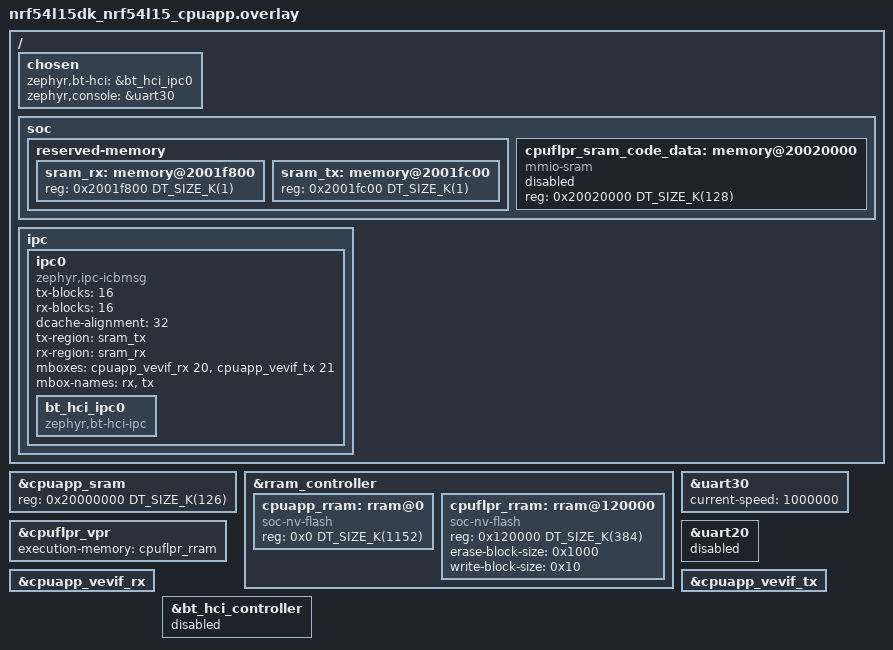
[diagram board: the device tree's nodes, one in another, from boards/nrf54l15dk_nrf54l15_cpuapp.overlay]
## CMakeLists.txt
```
# SPDX-License-Identifier: Apache-2.0

cmake_minimum_required(VERSION 3.28.0)

find_package(Zephyr REQUIRED HINTS $ENV{ZEPHYR_BASE})
project(peripheral_hr)

FILE(GLOB app_sources src/*.c)
target_sources(app PRIVATE
  ${app_sources}
  )

zephyr_library_include_directories(${ZEPHYR_BASE}/samples/bluetooth)
```

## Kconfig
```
# Copyright 2024 Nordic Semiconductor ASA
# SPDX-License-Identifier: Apache-2.0

if "$(FILE_SUFFIX)" = "extended"

# Increase Advertising Data Length, as Complete Local Name too needs to be
# placed in the AUX_ADV_IND PDU compared to when it is placed in ADV_SCAN_IND
# PDU in the case of legacy advertising.
configdefault BT_CTLR_ADV_DATA_LEN_MAX
	default 36

endif


if "$(FILE_SUFFIX)" = "phy_coded"

# Increase Advertising Data Length, as Complete Local Name too needs to be
# placed in the AUX_ADV_IND PDU compared to when it is placed in ADV_SCAN_IND
# PDU in the case of legacy advertising.
configdefault BT_CTLR_ADV_DATA_LEN_MAX
	default 36

configdefault BT_CTLR_PHY_CODED
	default y

endif


source "Kconfig"
```

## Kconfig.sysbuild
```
# Copyright 2023-2024 Nordic Semiconductor ASA
# SPDX-License-Identifier: Apache-2.0

source "share/sysbuild/Kconfig"

config NET_CORE_BOARD
	string
	default "nrf54l15dk/nrf54l15/cpuflpr" if $(BOARD) = "nrf54l15dk"
	default "nrf5340dk/nrf5340/cpunet" if $(BOARD) = "nrf5340dk"
	default "nrf5340_audio_dk/nrf5340/cpunet" if $(BOARD) = "nrf5340_audio_dk"
	default "nrf5340bsim/nrf5340/cpunet" if $(BOARD_TARGET_STRING) = "NRF5340BSIM_NRF5340_CPUAPP"

config NET_CORE_IMAGE_HCI_IPC
	bool "HCI IPC image on network core"
	default y
	depends on NET_CORE_BOARD != ""
```

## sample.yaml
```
sample:
  name: Bluetooth Peripheral HR
  description: Demonstrates the HR (Heart Rate) GATT Service
tests:
  sample.bluetooth.peripheral_hr:
    harness: bluetooth
    platform_allow:
      - qemu_cortex_m3
      - qemu_x86
      - nrf51dk/nrf51822
      - nrf52_bsim
      - nrf52dk/nrf52832
      - nrf52840dk/nrf52840
      - nrf5340bsim/nrf5340/cpuapp
      - nrf5340dk/nrf5340/cpuapp
      - nrf54l15bsim/nrf54l15/cpuapp
      - nrf54l15dk/nrf54l15/cpuapp
      - ophelia4ev/nrf54l15/cpuapp
      - nrf54lm20dk/nrf54lm20a/cpuapp
    integration_platforms:
      - qemu_cortex_m3
      - nrf51dk/nrf51822
      - nrf52_bsim
      - nrf52dk/nrf52832
      - nrf52840dk/nrf52840
      - nrf5340bsim/nrf5340/cpuapp
      - nrf5340dk/nrf5340/cpuapp
      - nrf54l15bsim/nrf54l15/cpuapp
      - nrf54l15dk/nrf54l15/cpuapp
      - ophelia4ev/nrf54l15/cpuapp
      - nrf54lm20dk/nrf54lm20a/cpuapp
    tags: bluetooth
    sysbuild: true
  sample.bluetooth.peripheral_hr.minimal:
    harness: bluetooth
    platform_allow:
      - qemu_cortex_m3
    integration_platforms:
      - qemu_cortex_m3
    extra_args:
      - CONF_FILE=prj_minimal.conf
    tags: bluetooth
  sample.bluetooth.peripheral_hr.bt_ll_sw_split.minimal:
    harness: bluetooth
    platform_allow:
      - bbc_microbit
      - nrf52dk/nrf52832
      - nrf54l15dk/nrf54l15/cpuapp
    integration_platforms:
      - bbc_microbit
      - nrf52dk/nrf52832
      - nrf54l15dk/nrf54l15/cpuapp
    extra_args:
      - CONF_FILE=prj_minimal.conf
      - EXTRA_CONF_FILE=overlay-bt_ll_sw_split-minimal.conf
    tags: bluetooth
  sample.bluetooth.peripheral_hr.bt_ll_sw_split.extended:
    harness: bluetooth
    platform_allow:
      - nrf52_bsim
      - nrf52dk/nrf52832
      - nrf52840dk/nrf52840
    integration_platforms:
      - nrf52_bsim
      - nrf52dk/nrf52832
      - nrf52840dk/nrf52840
    extra_args:
      - EXTRA_CONF_FILE=overlay-extended.conf
    tags: bluetooth
  sample.bluetooth.peripheral_hr.multicore.bt_ll_sw_split.extended:
    harness: bluetooth
    platform_allow:
      - nrf5340bsim/nrf5340/cpuapp
      - nrf5340dk/nrf5340/cpuapp
    integration_platforms:
      - nrf5340bsim/nrf5340/cpuapp
      - nrf5340dk/nrf5340/cpuapp
    extra_args:
      - CONFIG_BT_EXT_ADV=y
    tags: bluetooth
    sysbuild: true
  sample.bluetooth.peripheral_hr.bt_ll_sw_split.phy_coded:
    harness: bluetooth
    platform_allow:
      - nrf52_bsim
      - nrf52dk/nrf52832
      - nrf52840dk/nrf52840
    integration_platforms:
      - nrf52_bsim
      - nrf52dk/nrf52832
      - nrf52840dk/nrf52840
    extra_args:
      - EXTRA_CONF_FILE=overlay-phy_coded.conf
    tags: bluetooth
    sysbuild: true
  sample.bluetooth.peripheral_hr.multicore.bt_ll_sw_split.phy_coded:
    harness: bluetooth
    platform_allow:
      - nrf5340bsim/nrf5340/cpuapp
      - nrf5340dk/nrf5340/cpuapp
    integration_platforms:
      - nrf5340bsim/nrf5340/cpuapp
      - nrf5340dk/nrf5340/cpuapp
    extra_args:
      - CONFIG_BT_EXT_ADV=y
    tags: bluetooth
    sysbuild: true
  sample.bluetooth.peripheral_hr.bt_ll_sw_split.dual_timer:
    harness: bluetooth
    platform_allow:
      - nrf52_bsim
      - nrf52dk/nrf52832
      - nrf54l15bsim/nrf54l15/cpuapp
      - nrf54l15dk/nrf54l15/cpuapp
    integration_platforms:
      - nrf52_bsim
      - nrf52dk/nrf52832
      - nrf54l15bsim/nrf54l15/cpuapp
      - nrf54l15dk/nrf54l15/cpuapp
    extra_args:
      - CONFIG_BT_CTLR_ADVANCED_FEATURES=y
      - CONFIG_BT_CTLR_SW_SWITCH_SINGLE_TIMER=n
    tags: bluetooth
  sample.bluetooth.peripheral_hr.bt_ll_sw_split.single_timer:
    harness: bluetooth
    platform_allow:
      - nrf52_bsim
      - nrf52dk/nrf52832
      - nrf54l15bsim/nrf54l15/cpuapp
      - nrf54l15dk/nrf54l15/cpuapp
    integration_platforms:
      - nrf52_bsim
      - nrf52dk/nrf52832
      - nrf54l15bsim/nrf54l15/cpuapp
      - nrf54l15dk/nrf54l15/cpuapp
    extra_args:
      - CONFIG_BT_CTLR_ADVANCED_FEATURES=y
      - CONFIG_BT_CTLR_SW_SWITCH_SINGLE_TIMER=y
    tags: bluetooth
  sample.bluetooth.peripheral_hr_rv32m1_vega_openisa_rv32m1_ri5cy:
    platform_allow: rv32m1_vega/openisa_rv32m1/ri5cy
    tags: bluetooth
    build_only: true
  sample.bluetooth.peripheral_hr.frdm_kw41z_shield:
    harness: bluetooth
    depends_on: arduino_serial
    tags: bluetooth
    extra_args: SHIELD=frdm_kw41z
```

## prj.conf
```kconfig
CONFIG_BT=y
CONFIG_LOG=y
CONFIG_BT_SMP=y
CONFIG_BT_PERIPHERAL=y
CONFIG_BT_DIS=y
CONFIG_BT_DIS_PNP=n
CONFIG_BT_BAS=y
CONFIG_BT_HRS=y
CONFIG_BT_DEVICE_NAME="Zephyr Heartrate Sensor"
CONFIG_BT_DEVICE_APPEARANCE=833

CONFIG_SYSTEM_WORKQUEUE_STACK_MIN_SIZE_APP=1100
```

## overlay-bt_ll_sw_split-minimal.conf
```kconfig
# Zephyr open source Bluetooth Low Energy Controller
CONFIG_BT_LL_SW_SPLIT=y

# Disable Bluetooth controller features not needed
CONFIG_BT_CTLR_CONN_PARAM_REQ=n
CONFIG_BT_CTLR_EXT_REJ_IND=n
CONFIG_BT_CTLR_PER_INIT_FEAT_XCHG=n
CONFIG_BT_CTLR_MIN_USED_CHAN=n

# Buffer sizes
CONFIG_BT_CTLR_RX_BUFFERS=1

# Use link time optimization for code size reduction
CONFIG_ISR_TABLES_LOCAL_DECLARATION=y
CONFIG_LTO=y

# Generate .lst file, to find HCI h/w error event given PC
CONFIG_OUTPUT_DISASSEMBLY=y
CONFIG_OUTPUT_DISASSEMBLY_WITH_SOURCE=y
```

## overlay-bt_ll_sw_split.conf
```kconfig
# Configuration file to be used as an overlay to the hci_ipc sample for multi-core boards

CONFIG_BT_EXT_ADV=y

# Enable Coded PHY support
CONFIG_BT_CTLR_PHY_CODED=y

# Increase Advertising Data Length, as Complete Local Name too needs to be
# placed in the AUX_ADV_IND PDU compared to when it is placed in ADV_SCAN_IND
# PDU in the case of legacy advertising.
CONFIG_BT_CTLR_ADV_DATA_LEN_MAX=36
```

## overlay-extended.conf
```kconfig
CONFIG_BT_EXT_ADV=y

# Increase Advertising Data Length, as Complete Local Name too needs to be
# placed in the AUX_ADV_IND PDU compared to when it is placed in ADV_SCAN_IND
# PDU in the case of legacy advertising.
CONFIG_BT_CTLR_ADV_DATA_LEN_MAX=36
```

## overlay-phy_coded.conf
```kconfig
CONFIG_BT_EXT_ADV=y

# Enable Coded PHY support
CONFIG_BT_CTLR_PHY_CODED=y

# Increase Advertising Data Length, as Complete Local Name too needs to be
# placed in the AUX_ADV_IND PDU compared to when it is placed in ADV_SCAN_IND
# PDU in the case of legacy advertising.
CONFIG_BT_CTLR_ADV_DATA_LEN_MAX=36
```

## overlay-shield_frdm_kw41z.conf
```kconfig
#
# Copyright (c) 2018, NXP
#
# SPDX-License-Identifier: Apache-2.0
#

CONFIG_SHIELD_FRDM_KW41Z=y
```

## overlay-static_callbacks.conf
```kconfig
# Disable connection dynamic callbacks
CONFIG_BT_CONN_DYNAMIC_CALLBACKS=n
```

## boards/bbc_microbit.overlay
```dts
/*
 * SPDX-FileCopyrightText: Copyright The Zephyr Project Contributors
 * SPDX-License-Identifier: Apache-2.0
 */

/* The sample does not use the accelerometer. With its node enabled the driver
 * is built in as soon as the sensor subsystem is on, which the clock
 * calibration turns on, and brings the I2C driver with it.
 */
&mma8653fc {
	status = "disabled";
};
```

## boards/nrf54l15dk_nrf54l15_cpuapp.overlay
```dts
/*
 * Copyright (c) 2026 Nordic Semiconductor ASA
 *
 * SPDX-License-Identifier: Apache-2.0
 */

/ {
	chosen {
		zephyr,bt-hci = &bt_hci_ipc0;
		zephyr,console = &uart30;
	};

	soc {
		reserved-memory {
			#address-cells = <1>;
			#size-cells = <1>;

			sram_rx: memory@2001f800 {
				reg = <0x2001f800 DT_SIZE_K(1)>;
			};

			sram_tx: memory@2001fc00 {
				reg = <0x2001fc00 DT_SIZE_K(1)>;
			};
		};

		cpuflpr_sram_code_data: memory@20020000 {
			compatible = "mmio-sram";
			reg = <0x20020000 DT_SIZE_K(128)>;
			ranges = <0x0 0x20020000 DT_SIZE_K(128)>;
			status = "reserved";
			#address-cells = <1>;
			#size-cells = <1>;
		};
	};

	ipc {
		ipc0: ipc0 {
			compatible = "zephyr,ipc-icbmsg";
			tx-blocks = <16>;
			rx-blocks = <16>;
			dcache-alignment = <32>;
			tx-region = <&sram_tx>;
			rx-region = <&sram_rx>;
			mboxes = <&cpuapp_vevif_rx 20>, <&cpuapp_vevif_tx 21>;
			mbox-names = "rx", "tx";
			status = "okay";

			bt_hci_ipc0: bt_hci_ipc0 {
				compatible = "zephyr,bt-hci-ipc";
				status = "okay";
			};
		};
	};
};

&cpuapp_sram {
	reg = <0x20000000 DT_SIZE_K(126)>;
	ranges = <0x0 0x20000000 DT_SIZE_K(126)>;
};

&rram_controller {
	cpuapp_rram: rram@0 {
		compatible = "soc-nv-flash";
		reg = <0x0 DT_SIZE_K(1152)>;
		ranges = <0x0 0 DT_SIZE_K(1152)>;
	};

	cpuflpr_rram: rram@120000 {
		compatible = "soc-nv-flash";
		reg = <0x120000 DT_SIZE_K(384)>;
		ranges = <0x0 0x120000 DT_SIZE_K(384)>;
		erase-block-size = <0x1000>;
		write-block-size = <0x10>;
		#address-cells = <1>;
		#size-cells = <1>;
	};
};

&cpuflpr_vpr {
	status = "okay";
	execution-memory = <&cpuflpr_rram>;
	/*
	 * execution-memory = <&cpuflpr_sram_code_data>;
	 * source-memory = <&cpuflpr_rram>;
	 */
};

&uart30 {
	current-speed = <1000000>;
	status = "okay";
};

&uart20 {
	status = "disabled";
};

&cpuapp_vevif_rx {
	status = "okay";
};

&cpuapp_vevif_tx {
	status = "okay";
};

&bt_hci_controller {
	status = "disabled";
};
```

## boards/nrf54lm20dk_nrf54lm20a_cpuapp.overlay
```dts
/*
 * Copyright (c) 2026 Nordic Semiconductor ASA
 *
 * SPDX-License-Identifier: Apache-2.0
 */

/ {
	chosen {
		zephyr,bt-hci = &bt_hci_ipc0;
		zephyr,console = &uart30;
	};

	soc {
		reserved-memory {
			#address-cells = <1>;
			#size-cells = <1>;

			sram_rx: memory@2001F800 {
				reg = <0x2001F800 DT_SIZE_K(1)>;
			};

			sram_tx: memory@2001FC00 {
				reg = <0x2001FC00 DT_SIZE_K(1)>;
			};
		};

		cpuflpr_sram_code_data: memory@20020000 {
			compatible = "mmio-sram";
			reg = <0x20020000 DT_SIZE_K(128)>;
			ranges = <0x0 0x20020000 DT_SIZE_K(128)>;
			status = "reserved";
			#address-cells = <1>;
			#size-cells = <1>;
		};
	};

	ipc {
		ipc0: ipc0 {
			compatible = "zephyr,ipc-icbmsg";
			tx-blocks = <32>;
			rx-blocks = <32>;
			dcache-alignment = <32>;
			tx-region = <&sram_tx>;
			rx-region = <&sram_rx>;
			mboxes = <&cpuapp_vevif_rx 20>, <&cpuapp_vevif_tx 21>;
			mbox-names = "rx", "tx";
			status = "okay";

			bt_hci_ipc0: bt_hci_ipc0 {
				compatible = "zephyr,bt-hci-ipc";
				status = "okay";
			};
		};
	};
};

&cpuapp_sram {
	reg = <0x20000000 DT_SIZE_K(126)>;
	ranges = <0x0 0x20000000 DT_SIZE_K(126)>;
};

&rram_controller {
	cpuapp_rram: rram@0 {
		compatible = "soc-nv-flash";
		reg = <0x0 DT_SIZE_K(1280)>;
		ranges = <0x0 0 DT_SIZE_K(1280)>;
	};

	cpuflpr_rram: rram@140000 {
		compatible = "soc-nv-flash";
		reg = <0x140000 DT_SIZE_K(256)>;
		ranges = <0x0 0x140000 DT_SIZE_K(256)>;
		erase-block-size = <0x1000>;
		write-block-size = <0x10>;
		#address-cells = <1>;
		#size-cells = <1>;
	};
};

&cpuflpr_vpr {
	status = "okay";
	execution-memory = <&cpuflpr_rram>;
	/*
	 * execution-memory = <&cpuflpr_sram_code_data>;
	 * source-memory = <&cpuflpr_rram>;
	 */
};

&uart30 {
	current-speed = <1000000>;
	status = "okay";
};

&uart20 {
	status = "disabled";
};

&cpuapp_vevif_rx {
	status = "okay";
};

&cpuapp_vevif_tx {
	status = "okay";
};

&bt_hci_controller {
	status = "disabled";
};
```

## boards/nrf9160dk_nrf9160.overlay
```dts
/ {
	chosen {
		zephyr,bt-uart=&uart2;
	};
};

&uart2 {
	compatible = "nordic,nrf-uarte";
	current-speed = <1000000>;
	status = "okay";
	tx-pin = <18>;
	rx-pin = <17>;
	rts-pin = <21>;
	cts-pin = <19>;
	hw-flow-control;
};
```

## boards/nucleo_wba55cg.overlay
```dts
/*
 * SPDX-License-Identifier: Apache-2.0
 *
 * Copyright (c) 2023 STMicroelectronics
 */

/ {
	/* Change min residency time to ease power consumption measurement */
	cpus {
		cpu0: cpu@0 {
			cpu-power-states = <&stop0 &stop1 &standby>;
		};

		power-states {
			standby: state2 {
				compatible = "zephyr,power-state";
				power-state-name = "suspend-to-ram";
				substate-id = <1>;
				min-residency-us = <10000>;
				exit-latency-us = <1000>;
			};
		};
	};

};

&lptim1 {
	status = "okay";
};
```

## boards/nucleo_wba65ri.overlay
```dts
/*
 * SPDX-License-Identifier: Apache-2.0
 *
 * Copyright (c) 2023 STMicroelectronics
 */

/ {
	/* Change min residency time to ease power consumption measurement */
	cpus {
		cpu0: cpu@0 {
			cpu-power-states = <&stop0 &stop1 &standby>;
		};

		power-states {
			standby: state2 {
				compatible = "zephyr,power-state";
				power-state-name = "suspend-to-ram";
				substate-id = <1>;
				min-residency-us = <10000>;
				exit-latency-us = <1000>;
			};
		};
	};
};

&lptim1 {
	status = "okay";
};
```

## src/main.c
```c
/* main.c - Application main entry point */

/*
 * Copyright (c) 2024 Nordic Semiconductor ASA
 * Copyright (c) 2015-2016 Intel Corporation
 *
 * SPDX-License-Identifier: Apache-2.0
 */

#include <zephyr/device.h>
#include <zephyr/devicetree.h>

#include <zephyr/bluetooth/bluetooth.h>
#include <zephyr/bluetooth/hci.h>
#include <zephyr/bluetooth/conn.h>
#include <zephyr/bluetooth/uuid.h>
#include <zephyr/bluetooth/gatt.h>
#include <zephyr/bluetooth/services/bas.h>
#include <zephyr/bluetooth/services/hrs.h>

static bool hrf_ntf_enabled;

static const struct bt_data ad[] = {
	BT_DATA_BYTES(BT_DATA_FLAGS, (BT_LE_AD_GENERAL | BT_LE_AD_NO_BREDR)),
	BT_DATA_BYTES(BT_DATA_UUID16_ALL,
		      BT_UUID_16_ENCODE(BT_UUID_HRS_VAL),
		      BT_UUID_16_ENCODE(BT_UUID_BAS_VAL),
		      BT_UUID_16_ENCODE(BT_UUID_DIS_VAL)),
#if defined(CONFIG_BT_EXT_ADV)
	BT_DATA(BT_DATA_NAME_COMPLETE, CONFIG_BT_DEVICE_NAME, sizeof(CONFIG_BT_DEVICE_NAME) - 1),
#endif /* CONFIG_BT_EXT_ADV */
};

#if !defined(CONFIG_BT_EXT_ADV)
static const struct bt_data sd[] = {
	BT_DATA(BT_DATA_NAME_COMPLETE, CONFIG_BT_DEVICE_NAME, sizeof(CONFIG_BT_DEVICE_NAME) - 1),
};
#endif /* !CONFIG_BT_EXT_ADV */

enum {
	STATE_CONNECTED,
	STATE_DISCONNECTED,

	STATE_BITS,
};

static ATOMIC_DEFINE(state, STATE_BITS);

static void connected(struct bt_conn *conn, uint8_t err)
{
	if (err) {
		printk("Connection failed, err 0x%02x %s\n", err, bt_hci_err_to_str(err));
	} else {
		printk("Connected\n");

		(void)atomic_set_bit(state, STATE_CONNECTED);
	}
}

static void disconnected(struct bt_conn *conn, uint8_t reason)
{
	printk("Disconnected, reason 0x%02x %s\n", reason, bt_hci_err_to_str(reason));

	(void)atomic_set_bit(state, STATE_DISCONNECTED);
}

BT_CONN_CB_DEFINE(conn_callbacks) = {
	.connected = connected,
	.disconnected = disconnected,
};

static void hrs_ntf_changed(bool enabled)
{
	hrf_ntf_enabled = enabled;

	printk("HRS notification status changed: %s\n",
	       enabled ? "enabled" : "disabled");
}

static struct bt_hrs_cb hrs_cb = {
	.ntf_changed = hrs_ntf_changed,
};

static void auth_cancel(struct bt_conn *conn)
{
	printk("Pairing cancelled: %s\n", bt_conn_dst_str(conn));
}

static struct bt_conn_auth_cb auth_cb_display = {
	.cancel = auth_cancel,
};

static void bas_notify(void)
{
	uint8_t battery_level = bt_bas_get_battery_level();

	battery_level--;

	if (!battery_level) {
		battery_level = 100U;
	}

	bt_bas_set_battery_level(battery_level);
}

static void hrs_notify(void)
{
	static uint8_t heartrate = 90U;

	/* Heartrate measurements simulation */
	heartrate++;
	if (heartrate == 160U) {
		heartrate = 90U;
	}

	if (hrf_ntf_enabled) {
		bt_hrs_notify(heartrate);
	}
}

#if defined(CONFIG_GPIO)
/* The devicetree node identifier for the "led0" alias. */
#define LED0_NODE DT_ALIAS(led0)

#if DT_NODE_HAS_STATUS_OKAY(LED0_NODE)
#include <zephyr/drivers/gpio.h>
#define HAS_LED     1
static const struct gpio_dt_spec led = GPIO_DT_SPEC_GET(LED0_NODE, gpios);
#define BLINK_ONOFF K_MSEC(500)

static struct k_work_delayable blink_work;
static bool                  led_is_on;

static void blink_timeout(struct k_work *work)
{
	led_is_on = !led_is_on;
	gpio_pin_set(led.port, led.pin, (int)led_is_on);

	k_work_schedule(&blink_work, BLINK_ONOFF);
}

static int blink_setup(void)
{
	int err;

	printk("Checking LED device...");
	if (!gpio_is_ready_dt(&led)) {
		printk("failed.\n");
		return -EIO;
	}
	printk("done.\n");

	printk("Configuring GPIO pin...");
	err = gpio_pin_configure_dt(&led, GPIO_OUTPUT_ACTIVE);
	if (err) {
		printk("failed.\n");
		return -EIO;
	}
	printk("done.\n");

	k_work_init_delayable(&blink_work, blink_timeout);

	return 0;
}

static void blink_start(void)
{
	printk("Start blinking LED...\n");
	led_is_on = false;
	gpio_pin_set(led.port, led.pin, (int)led_is_on);
	k_work_schedule(&blink_work, BLINK_ONOFF);
}

static void blink_stop(void)
{
	struct k_work_sync work_sync;

	printk("Stop blinking LED.\n");
	k_work_cancel_delayable_sync(&blink_work, &work_sync);

	/* Keep LED on */
	led_is_on = true;
	gpio_pin_set(led.port, led.pin, (int)led_is_on);
}
#endif /* LED0_NODE */
#endif /* CONFIG_GPIO */

int main(void)
{
	int err;

	err = bt_enable(NULL);
	if (err) {
		printk("Bluetooth init failed (err %d)\n", err);
		return 0;
	}

	printk("Bluetooth initialized\n");

	bt_conn_auth_cb_register(&auth_cb_display);

	bt_hrs_cb_register(&hrs_cb);

#if !defined(CONFIG_BT_EXT_ADV)
	printk("Starting Legacy Advertising (connectable and scannable)\n");
	err = bt_le_adv_start(BT_LE_ADV_CONN_FAST_1, ad, ARRAY_SIZE(ad), sd, ARRAY_SIZE(sd));
	if (err) {
		printk("Advertising failed to start (err %d)\n", err);
		return 0;
	}

#else /* CONFIG_BT_EXT_ADV */
	struct bt_le_adv_param adv_param = {
		.id = BT_ID_DEFAULT,
		.sid = 0U,
		.secondary_max_skip = 0U,
		.options = (BT_LE_ADV_OPT_EXT_ADV | BT_LE_ADV_OPT_CONN | BT_LE_ADV_OPT_CODED),
		.interval_min = BT_GAP_ADV_FAST_INT_MIN_2,
		.interval_max = BT_GAP_ADV_FAST_INT_MAX_2,
		.peer = NULL,
	};
	struct bt_le_ext_adv *adv;

	printk("Creating a Coded PHY connectable non-scannable advertising set\n");
	err = bt_le_ext_adv_create(&adv_param, NULL, &adv);
	if (err) {
		printk("Failed to create Coded PHY extended advertising set (err %d)\n", err);

		printk("Creating a non-Coded PHY connectable non-scannable advertising set\n");
		adv_param.options &= ~BT_LE_ADV_OPT_CODED;
		err = bt_le_ext_adv_create(&adv_param, NULL, &adv);
		if (err) {
			printk("Failed to create extended advertising set (err %d)\n", err);
			return 0;
		}
	}

	printk("Setting extended advertising data\n");
	err = bt_le_ext_adv_set_data(adv, ad, ARRAY_SIZE(ad), NULL, 0);
	if (err) {
		printk("Failed to set extended advertising data (err %d)\n", err);
		return 0;
	}

	printk("Starting Extended Advertising (connectable non-scannable)\n");
	err = bt_le_ext_adv_start(adv, BT_LE_EXT_ADV_START_DEFAULT);
	if (err) {
		printk("Failed to start extended advertising set (err %d)\n", err);
		return 0;
	}
#endif /* CONFIG_BT_EXT_ADV */

	printk("Advertising successfully started\n");

#if defined(HAS_LED)
	err = blink_setup();
	if (err) {
		return 0;
	}

	blink_start();
#endif /* HAS_LED */

	/* Implement notification. */
	while (1) {
		k_sleep(K_SECONDS(1));

		/* Heartrate measurements simulation */
		hrs_notify();

		/* Battery level simulation */
		bas_notify();

		if (atomic_test_and_clear_bit(state, STATE_CONNECTED)) {
			/* Connected callback executed */

#if defined(HAS_LED)
			blink_stop();
#endif /* HAS_LED */
		} else if (atomic_test_and_clear_bit(state, STATE_DISCONNECTED)) {
#if !defined(CONFIG_BT_EXT_ADV)
			printk("Starting Legacy Advertising (connectable and scannable)\n");
			err = bt_le_adv_start(BT_LE_ADV_CONN_FAST_1, ad, ARRAY_SIZE(ad), sd,
					      ARRAY_SIZE(sd));
			if (err) {
				printk("Advertising failed to start (err %d)\n", err);
				return 0;
			}

#else /* CONFIG_BT_EXT_ADV */
			printk("Starting Extended Advertising (connectable and non-scannable)\n");
			err = bt_le_ext_adv_start(adv, BT_LE_EXT_ADV_START_DEFAULT);
			if (err) {
				printk("Failed to start extended advertising set (err %d)\n", err);
				return 0;
			}
#endif /* CONFIG_BT_EXT_ADV */

#if defined(HAS_LED)
			blink_start();
#endif /* HAS_LED */
		}
	}

	return 0;
}
```

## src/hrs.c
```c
/* Workaround build system bug that will put objects in source dir */
#include "../../gatt/hrs.c"
```
